AUTOSAR XML (schema 4-1-3)
standard types defined: boolean, sint16, uint16, uint32, uint8
package /UAES/ASW/CompuMethods
  compu method CM_boolean: 0=FALSE, 1=TRUE
package /UAES/ASW/DataConstrs
  range DC_boolean: raw 0..1
  range DC_sint16: raw -32768..32767
  range DC_uint16: raw 0..65535
  range DC_uint32: raw 0..4294967295
  range DC_uint8: raw 0..255
package /UAES/ASW/DataTypeMappingSets
  data type mapping set DTMS_ElecDoorHndlHall_DD
package /UAES/ASW/PortInterfaces
  client server interface IoHwAb_IoSigAdc
    operation Adc_Get: possible-error=IoHwAb_IoSigAdc/E_NOT_OK
      arg id_u16: type=uint16, direction=IN, server-argument-impl-policy=USE-ARGUMENT-TYPE
      arg val_s16: type=sint16, direction=OUT, server-argument-impl-policy=USE-ARGUMENT-TYPE
    operation AdcFac_Get: possible-error=IoHwAb_IoSigAdc/E_NOT_OK
      arg id_u16: type=uint16, direction=IN, server-argument-impl-policy=USE-ARGUMENT-TYPE
      arg val_s16: type=sint16, direction=OUT, server-argument-impl-policy=USE-ARGUMENT-TYPE
    operation AdcVRMBatt_Get: possible-error=IoHwAb_IoSigAdc/E_NOT_OK
      arg id_u16: type=uint16, direction=IN, server-argument-impl-policy=USE-ARGUMENT-TYPE
      arg val_u8: type=uint8, direction=OUT, server-argument-impl-policy=USE-ARGUMENT-TYPE
    error E_NOT_OK: error-code=1
  client server interface IoHwAb_IoSigIcu
    operation Icu_GetEdgeNumbers: possible-error=IoHwAb_IoSigIcu/E_NOT_OK
      arg id_u16: type=uint16, direction=IN, server-argument-impl-policy=USE-ARGUMENT-TYPE
      arg numval_u32: type=uint32, direction=OUT, server-argument-impl-policy=USE-ARGUMENT-TYPE
    operation Icu_GetPerdAndDuty: possible-error=IoHwAb_IoSigIcu/E_NOT_OK
      arg id_u16: type=uint16, direction=IN, server-argument-impl-policy=USE-ARGUMENT-TYPE
      arg duty_u32: type=uint32, direction=OUT, server-argument-impl-policy=USE-ARGUMENT-TYPE
      arg period_u32: type=uint32, direction=OUT, server-argument-impl-policy=USE-ARGUMENT-TYPE
    error E_NOT_OK: error-code=1
  16 x sender receiver interface:
    BattU_bVoltEnbPinDiag: invalidation-policy{data-element=BattU_bVoltEnbPinDiag/Val, handle-invalid=DONT-INVALIDATE}
      data Val: sw-calibration-access=READ-ONLY, type=boolean
    gEDH_u16FLHallCnt: invalidation-policy{data-element=gEDH_u16FLHallCnt/Val, handle-invalid=DONT-INVALIDATE}
      data Val: sw-calibration-access=READ-ONLY, type=uint16
    gEDH_u16FRHallCnt: invalidation-policy{data-element=gEDH_u16FRHallCnt/Val, handle-invalid=DONT-INVALIDATE}
      data Val: sw-calibration-access=READ-ONLY, type=uint16
    gEDH_u16RLHallCnt: invalidation-policy{data-element=gEDH_u16RLHallCnt/Val, handle-invalid=DONT-INVALIDATE}
      data Val: sw-calibration-access=READ-ONLY, type=uint16
    gEDH_u16RRHallCnt: invalidation-policy{data-element=gEDH_u16RRHallCnt/Val, handle-invalid=DONT-INVALIDATE}
      data Val: sw-calibration-access=READ-ONLY, type=uint16
    gElecDoorHndl_u8FLDoorHndlMotorPs: invalidation-policy{data-element=gElecDoorHndl_u8FLDoorHndlMotorPs/Val, handle-invalid=DONT-INVALIDATE}
      data Val: sw-calibration-access=READ-ONLY, type=uint8
    gElecDoorHndl_u8FRDoorHndlMotorPs: invalidation-policy{data-element=gElecDoorHndl_u8FRDoorHndlMotorPs/Val, handle-invalid=DONT-INVALIDATE}
      data Val: sw-calibration-access=READ-ONLY, type=uint8
    gElecDoorHndl_u8RLDoorHndlMotorPs: invalidation-policy{data-element=gElecDoorHndl_u8RLDoorHndlMotorPs/Val, handle-invalid=DONT-INVALIDATE}
      data Val: sw-calibration-access=READ-ONLY, type=uint8
    gElecDoorHndl_u8RRDoorHndlMotorPs: invalidation-policy{data-element=gElecDoorHndl_u8RRDoorHndlMotorPs/Val, handle-invalid=DONT-INVALIDATE}
      data Val: sw-calibration-access=READ-ONLY, type=uint8
    gElecDoorHndlHall_u16FLDoorHandleHallAD: invalidation-policy{data-element=gElecDoorHndlHall_u16FLDoorHandleHallAD/Val, handle-invalid=DONT-INVALIDATE}
      data Val: sw-calibration-access=READ-ONLY, type=uint16
    gElecDoorHndlHall_u16FLDoorHandleHallAD1: invalidation-policy{data-element=gElecDoorHndlHall_u16FLDoorHandleHallAD1/Val, handle-invalid=DONT-INVALIDATE}
      data Val: sw-calibration-access=READ-ONLY, type=uint16
    gElecDoorHndlHall_u16FRDoorHandleHallAD: invalidation-policy{data-element=gElecDoorHndlHall_u16FRDoorHandleHallAD/Val, handle-invalid=DONT-INVALIDATE}
      data Val: sw-calibration-access=READ-ONLY, type=uint16
    gElecDoorHndlHall_u16FRDoorHandleHallAD1: invalidation-policy{data-element=gElecDoorHndlHall_u16FRDoorHandleHallAD1/Val, handle-invalid=DONT-INVALIDATE}
      data Val: sw-calibration-access=READ-ONLY, type=uint16
    gElecDoorHndlHall_u16RLDoorHandleHallAD: invalidation-policy{data-element=gElecDoorHndlHall_u16RLDoorHandleHallAD/Val, handle-invalid=DONT-INVALIDATE}
      data Val: sw-calibration-access=READ-ONLY, type=uint16
    gElecDoorHndlHall_u16RLDoorHandleHallAD1: invalidation-policy{data-element=gElecDoorHndlHall_u16RLDoorHandleHallAD1/Val, handle-invalid=DONT-INVALIDATE}
      data Val: sw-calibration-access=READ-ONLY, type=uint16
    gElecDoorHndlHall_u16RRDoorHandleHallAD: invalidation-policy{data-element=gElecDoorHndlHall_u16RRDoorHandleHallAD/Val, handle-invalid=DONT-INVALIDATE}
      data Val: sw-calibration-access=READ-ONLY, type=uint16
package /UAES/ASW/SwComponentTypes
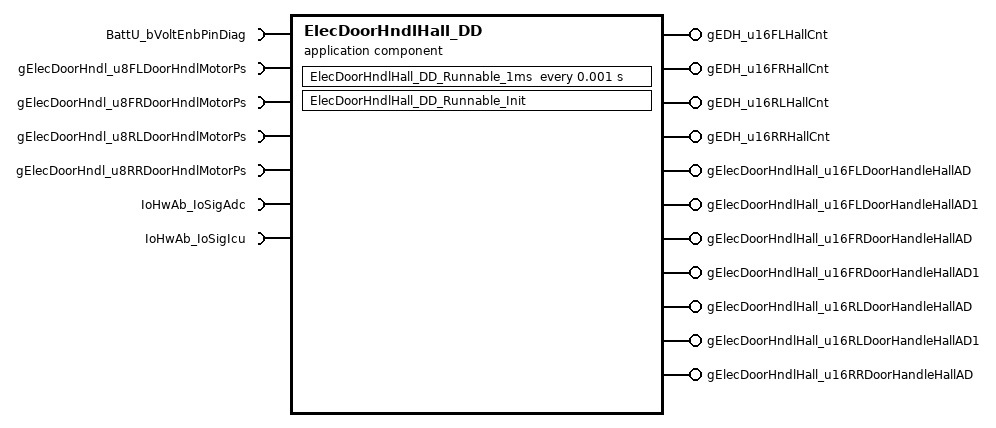
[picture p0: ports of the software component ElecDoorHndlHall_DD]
  application sw component type ElecDoorHndlHall_DD
    11 x provide port:
      gEDH_u16FLHallCnt: nonqueued-sender-com-spec{data-element=gEDH_u16FLHallCnt/Val, init-value=0}, provided-interface=gEDH_u16FLHallCnt
      gEDH_u16FRHallCnt: nonqueued-sender-com-spec{data-element=gEDH_u16FRHallCnt/Val, init-value=0}, provided-interface=gEDH_u16FRHallCnt
      gEDH_u16RLHallCnt: nonqueued-sender-com-spec{data-element=gEDH_u16RLHallCnt/Val, init-value=0}, provided-interface=gEDH_u16RLHallCnt
      gEDH_u16RRHallCnt: nonqueued-sender-com-spec{data-element=gEDH_u16RRHallCnt/Val, init-value=0}, provided-interface=gEDH_u16RRHallCnt
      gElecDoorHndlHall_u16FLDoorHandleHallAD: nonqueued-sender-com-spec{data-element=gElecDoorHndlHall_u16FLDoorHandleHallAD/Val, init-value=0}, provided-interface=gElecDoorHndlHall_u16FLDoorHandleHallAD
      gElecDoorHndlHall_u16FLDoorHandleHallAD1: nonqueued-sender-com-spec{data-element=gElecDoorHndlHall_u16FLDoorHandleHallAD1/Val, init-value=0}, provided-interface=gElecDoorHndlHall_u16FLDoorHandleHallAD1
      gElecDoorHndlHall_u16FRDoorHandleHallAD: nonqueued-sender-com-spec{data-element=gElecDoorHndlHall_u16FRDoorHandleHallAD/Val, init-value=0}, provided-interface=gElecDoorHndlHall_u16FRDoorHandleHallAD
      gElecDoorHndlHall_u16FRDoorHandleHallAD1: nonqueued-sender-com-spec{data-element=gElecDoorHndlHall_u16FRDoorHandleHallAD1/Val, init-value=0}, provided-interface=gElecDoorHndlHall_u16FRDoorHandleHallAD1
      gElecDoorHndlHall_u16RLDoorHandleHallAD: nonqueued-sender-com-spec{data-element=gElecDoorHndlHall_u16RLDoorHandleHallAD/Val, init-value=0}, provided-interface=gElecDoorHndlHall_u16RLDoorHandleHallAD
      gElecDoorHndlHall_u16RLDoorHandleHallAD1: nonqueued-sender-com-spec{data-element=gElecDoorHndlHall_u16RLDoorHandleHallAD1/Val, init-value=0}, provided-interface=gElecDoorHndlHall_u16RLDoorHandleHallAD1
      gElecDoorHndlHall_u16RRDoorHandleHallAD: nonqueued-sender-com-spec{data-element=gElecDoorHndlHall_u16RRDoorHandleHallAD/Val, init-value=0}, provided-interface=gElecDoorHndlHall_u16RRDoorHandleHallAD
    7 x require port:
      BattU_bVoltEnbPinDiag: nonqueued-receiver-com-spec{data-element=BattU_bVoltEnbPinDiag/Val, filter=data-filter-type=ALWAYS, init-value=0}, required-interface=BattU_bVoltEnbPinDiag
      gElecDoorHndl_u8FLDoorHndlMotorPs: nonqueued-receiver-com-spec{data-element=gElecDoorHndl_u8FLDoorHndlMotorPs/Val, filter=data-filter-type=ALWAYS, init-value=0}, required-interface=gElecDoorHndl_u8FLDoorHndlMotorPs
      gElecDoorHndl_u8FRDoorHndlMotorPs: nonqueued-receiver-com-spec{data-element=gElecDoorHndl_u8FRDoorHndlMotorPs/Val, filter=data-filter-type=ALWAYS, init-value=0}, required-interface=gElecDoorHndl_u8FRDoorHndlMotorPs
      gElecDoorHndl_u8RLDoorHndlMotorPs: nonqueued-receiver-com-spec{data-element=gElecDoorHndl_u8RLDoorHndlMotorPs/Val, filter=data-filter-type=ALWAYS, init-value=0}, required-interface=gElecDoorHndl_u8RLDoorHndlMotorPs
      gElecDoorHndl_u8RRDoorHndlMotorPs: nonqueued-receiver-com-spec{data-element=gElecDoorHndl_u8RRDoorHndlMotorPs/Val, filter=data-filter-type=ALWAYS, init-value=0}, required-interface=gElecDoorHndl_u8RRDoorHndlMotorPs
      IoHwAb_IoSigAdc: required-com-specs=[Adc_Get, AdcFac_Get, AdcVRMBatt_Get], required-interface=IoHwAb_IoSigAdc
      IoHwAb_IoSigIcu: required-com-specs=[Icu_GetEdgeNumbers, Icu_GetPerdAndDuty], required-interface=IoHwAb_IoSigIcu
    behavior ElecDoorHndlHall_DD_InternalBehavior: data-type-mapping=DTMS_ElecDoorHndlHall_DD
      timing event TMT_ElecDoorHndlHall_DD_Runnable_1ms: start-on-event=ElecDoorHndlHall_DD_Runnable_1ms, period=0.001
      init event ElecDoorHndlHall_DD_InitEvent: start-on-event=ElecDoorHndlHall_DD_Runnable_Init
      runnable ElecDoorHndlHall_DD_Runnable_1ms
        data-receive-point-by-arguments:
          5 x access:
            REC_BattU_bVoltEnbPinDiag_Val: accessed-variable=BattU_bVoltEnbPinDiag.Val
            REC_gElecDoorHndl_u8FLDoorHndlMotorPs_Val: accessed-variable=gElecDoorHndl_u8FLDoorHndlMotorPs.Val
            REC_gElecDoorHndl_u8FRDoorHndlMotorPs_Val: accessed-variable=gElecDoorHndl_u8FRDoorHndlMotorPs.Val
            REC_gElecDoorHndl_u8RLDoorHndlMotorPs_Val: accessed-variable=gElecDoorHndl_u8RLDoorHndlMotorPs.Val
            REC_gElecDoorHndl_u8RRDoorHndlMotorPs_Val: accessed-variable=gElecDoorHndl_u8RRDoorHndlMotorPs.Val
        data-send-points:
          11 x access:
            SEND_gEDH_u16FLHallCnt_Val: accessed-variable=gEDH_u16FLHallCnt.Val
            SEND_gEDH_u16FRHallCnt_Val: accessed-variable=gEDH_u16FRHallCnt.Val
            SEND_gEDH_u16RLHallCnt_Val: accessed-variable=gEDH_u16RLHallCnt.Val
            SEND_gEDH_u16RRHallCnt_Val: accessed-variable=gEDH_u16RRHallCnt.Val
            SEND_gElecDoorHndlHall_u16FLDoorHandleHallAD_Val: accessed-variable=gElecDoorHndlHall_u16FLDoorHandleHallAD.Val
            SEND_gElecDoorHndlHall_u16FLDoorHandleHallAD1_Val: accessed-variable=gElecDoorHndlHall_u16FLDoorHandleHallAD1.Val
            SEND_gElecDoorHndlHall_u16FRDoorHandleHallAD_Val: accessed-variable=gElecDoorHndlHall_u16FRDoorHandleHallAD.Val
            SEND_gElecDoorHndlHall_u16FRDoorHandleHallAD1_Val: accessed-variable=gElecDoorHndlHall_u16FRDoorHandleHallAD1.Val
            SEND_gElecDoorHndlHall_u16RLDoorHandleHallAD_Val: accessed-variable=gElecDoorHndlHall_u16RLDoorHandleHallAD.Val
            SEND_gElecDoorHndlHall_u16RLDoorHandleHallAD1_Val: accessed-variable=gElecDoorHndlHall_u16RLDoorHandleHallAD1.Val
            SEND_gElecDoorHndlHall_u16RRDoorHandleHallAD_Val: accessed-variable=gElecDoorHndlHall_u16RRDoorHandleHallAD.Val
        sync call SC_IoHwAb_IoSigAdc_AdcFac_Get: operation=IoHwAb_IoSigAdc.AdcFac_Get, timeout=0
        sync call SC_IoHwAb_IoSigIcu_Icu_GetEdgeNumbers: operation=IoHwAb_IoSigIcu.Icu_GetEdgeNumbers, timeout=0
        sync call SC_IoHwAb_IoSigIcu_Icu_GetPerdAndDuty: operation=IoHwAb_IoSigIcu.Icu_GetPerdAndDuty, timeout=0
      runnable ElecDoorHndlHall_DD_Runnable_Init
  swc implementation ElecDoorHndlHall_DD_Implementation: behavior=ElecDoorHndlHall_DD_InternalBehavior
    code-descriptors:
      code Default: artifact-descriptors=autosar-engineering-object={short-label=Default, category=SWSRC}
package /UAES/ASW/Units
  unit NoUnit: factor-si-to-unit=1, offset-si-to-unit=0
